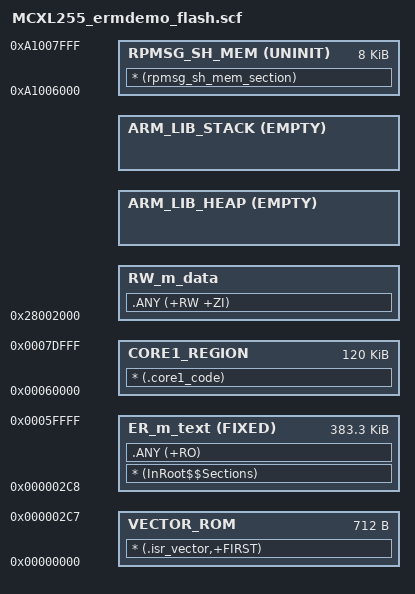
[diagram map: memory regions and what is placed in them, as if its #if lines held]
#!armclang --target=arm-arm-none-eabi -march=armv8-m.main -E -x c
/*
** ###################################################################
**     Processors:          MCXL255VDF_cm33
**                          MCXL255VLL_cm33
**
**     Compiler:            Keil ARM C/C++ Compiler
**     Reference manual:    MCXL25xRM DraftH
**     Version:             rev. 1.0, 2025-06-13
**     Build:               b250811
**
**     Abstract:
**         Linker file for the Keil ARM C/C++ Compiler
**
**     Copyright 2016 Freescale Semiconductor, Inc.
**     Copyright 2016-2025 NXP
**     SPDX-License-Identifier: BSD-3-Clause
**
**     http:                 www.nxp.com
**     mail:                 support@nxp.com
**
** ###################################################################
*/


/* Sizes */
#if (defined(__stack_size__))
  #define Stack_Size                   __stack_size__
#else
  #define Stack_Size                   0x0400
#endif

#if (defined(__heap_size__))
  #define Heap_Size                    __heap_size__
#else
  #define Heap_Size                    0x0400
#endif

#define  m_interrupts_start            0x00000000
#define  m_interrupts_size             0x000002C8

#define  m_text_start                  0x000002C8
#define  m_text_size                   0x0005FD38

#define  m_core1_image_start           0x00060000
#define  m_core1_image_size            0x0001E000

#if (defined(__use_shmem__))
  #define  m_rpmsg_sh_mem_start        0xA1006000
  #define  m_rpmsg_sh_mem_size         0x00002000
#endif

/* Left ECC mem  0x28000000 - 0x28001FFF without any code or data. */
#define  m_data_start                  0x28002000
#define  m_data_size                   0x0001E000

#define  m_sramx0_start                0x04000000
#define  m_sramx0_size                 0x00002000

LR_m_text m_interrupts_start m_interrupts_size+m_text_size {   ; load region size_region

  VECTOR_ROM m_interrupts_start m_interrupts_size { ; load address = execution address
    * (.isr_vector,+FIRST)
  }

  ER_m_text m_text_start FIXED m_text_size { ; load address = execution address
    * (InRoot$$Sections)
    .ANY (+RO)
  }

  RW_m_data m_data_start m_data_size-Stack_Size-Heap_Size { ; RW data
    .ANY (+RW +ZI)
  }
  ARM_LIB_HEAP +0 EMPTY Heap_Size {    ; Heap region growing up
  }
  ARM_LIB_STACK m_data_start+m_data_size EMPTY -Stack_Size { ; Stack region growing down
  }

#if (defined(__use_shmem__))
  RPMSG_SH_MEM m_rpmsg_sh_mem_start UNINIT m_rpmsg_sh_mem_size { ; Shared memory used by RPMSG
    * (rpmsg_sh_mem_section)
  }
#endif

}

LR_CORE1_IMAGE m_core1_image_start {
  CORE1_REGION m_core1_image_start m_core1_image_size {
    * (.core1_code)
  }
}
